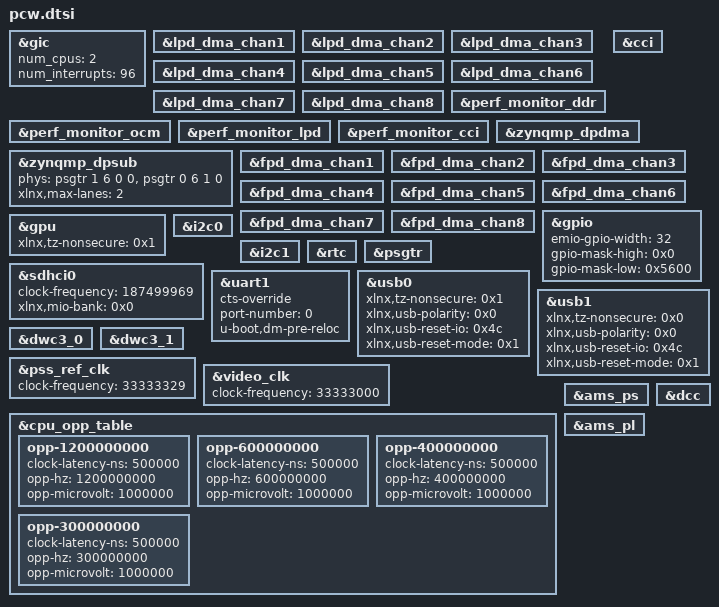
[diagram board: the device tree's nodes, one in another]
/*
 * CAUTION: This file is automatically generated by Xilinx.
 * Version: XSCT 2025.2
 * Today is: Sun Aug  2 20:15:27 2026
 */


&gic {
	num_cpus = <2>;
	num_interrupts = <96>;
};
&lpd_dma_chan1 {
	status = "okay";
};
&lpd_dma_chan2 {
	status = "okay";
};
&lpd_dma_chan3 {
	status = "okay";
};
&lpd_dma_chan4 {
	status = "okay";
};
&lpd_dma_chan5 {
	status = "okay";
};
&lpd_dma_chan6 {
	status = "okay";
};
&lpd_dma_chan7 {
	status = "okay";
};
&lpd_dma_chan8 {
	status = "okay";
};
&perf_monitor_ddr {
	status = "okay";
};
&perf_monitor_ocm {
	status = "okay";
};
&perf_monitor_lpd {
	status = "okay";
};
&perf_monitor_cci {
	status = "okay";
};
&cci {
	status = "okay";
};
&zynqmp_dpsub {
	phy-names = "dp-phy0","dp-phy1";
	phys = <&psgtr 1 6 0 0>, <&psgtr 0 6 1 0>;
	status = "okay";
	xlnx,max-lanes = <2>;
};
&zynqmp_dpdma {
	status = "okay";
};
&fpd_dma_chan1 {
	status = "okay";
};
&fpd_dma_chan2 {
	status = "okay";
};
&fpd_dma_chan3 {
	status = "okay";
};
&fpd_dma_chan4 {
	status = "okay";
};
&fpd_dma_chan5 {
	status = "okay";
};
&fpd_dma_chan6 {
	status = "okay";
};
&fpd_dma_chan7 {
	status = "okay";
};
&fpd_dma_chan8 {
	status = "okay";
};
&gpio {
	emio-gpio-width = <32>;
	gpio-mask-high = <0x0>;
	gpio-mask-low = <0x5600>;
	status = "okay";
};
&gpu {
	status = "okay";
	xlnx,tz-nonsecure = <0x1>;
};
&i2c0 {
	status = "okay";
};
&i2c1 {
	status = "okay";
};
&rtc {
	status = "okay";
};
&sdhci0 {
	clock-frequency = <187499969>;
	status = "okay";
	xlnx,mio-bank = <0x0>;
};
&psgtr {
	status = "okay";
};
&uart1 {
	cts-override ;
	device_type = "serial";
	port-number = <0>;
	status = "okay";
	u-boot,dm-pre-reloc ;
};
&usb0 {
	status = "okay";
	xlnx,tz-nonsecure = <0x1>;
	xlnx,usb-polarity = <0x0>;
	xlnx,usb-reset-io = <0x4c>;
	xlnx,usb-reset-mode = <0x1>;
};
&usb1 {
	status = "okay";
	xlnx,tz-nonsecure = <0x0>;
	xlnx,usb-polarity = <0x0>;
	xlnx,usb-reset-io = <0x4c>;
	xlnx,usb-reset-mode = <0x1>;
};
&dwc3_0 {
	status = "okay";
};
&dwc3_1 {
	status = "okay";
};
&pss_ref_clk {
	clock-frequency = <33333329>;
};
&video_clk {
	clock-frequency = <33333000>;
};
&cpu_opp_table {
	/delete-node/ opp00 ;
	/delete-node/ opp01 ;
	/delete-node/ opp02 ;
	/delete-node/ opp03 ;
	opp-1200000000 {
		clock-latency-ns = <500000>;
		opp-hz = /bits/ 64 <1200000000>;
		opp-microvolt = <1000000>;
	};
	opp-600000000 {
		clock-latency-ns = <500000>;
		opp-hz = /bits/ 64 <600000000>;
		opp-microvolt = <1000000>;
	};
	opp-400000000 {
		clock-latency-ns = <500000>;
		opp-hz = /bits/ 64 <400000000>;
		opp-microvolt = <1000000>;
	};
	opp-300000000 {
		clock-latency-ns = <500000>;
		opp-hz = /bits/ 64 <300000000>;
		opp-microvolt = <1000000>;
	};
};
&ams_ps {
	status = "okay";
};
&ams_pl {
	status = "okay";
};
&dcc {
	status = "okay";
};
